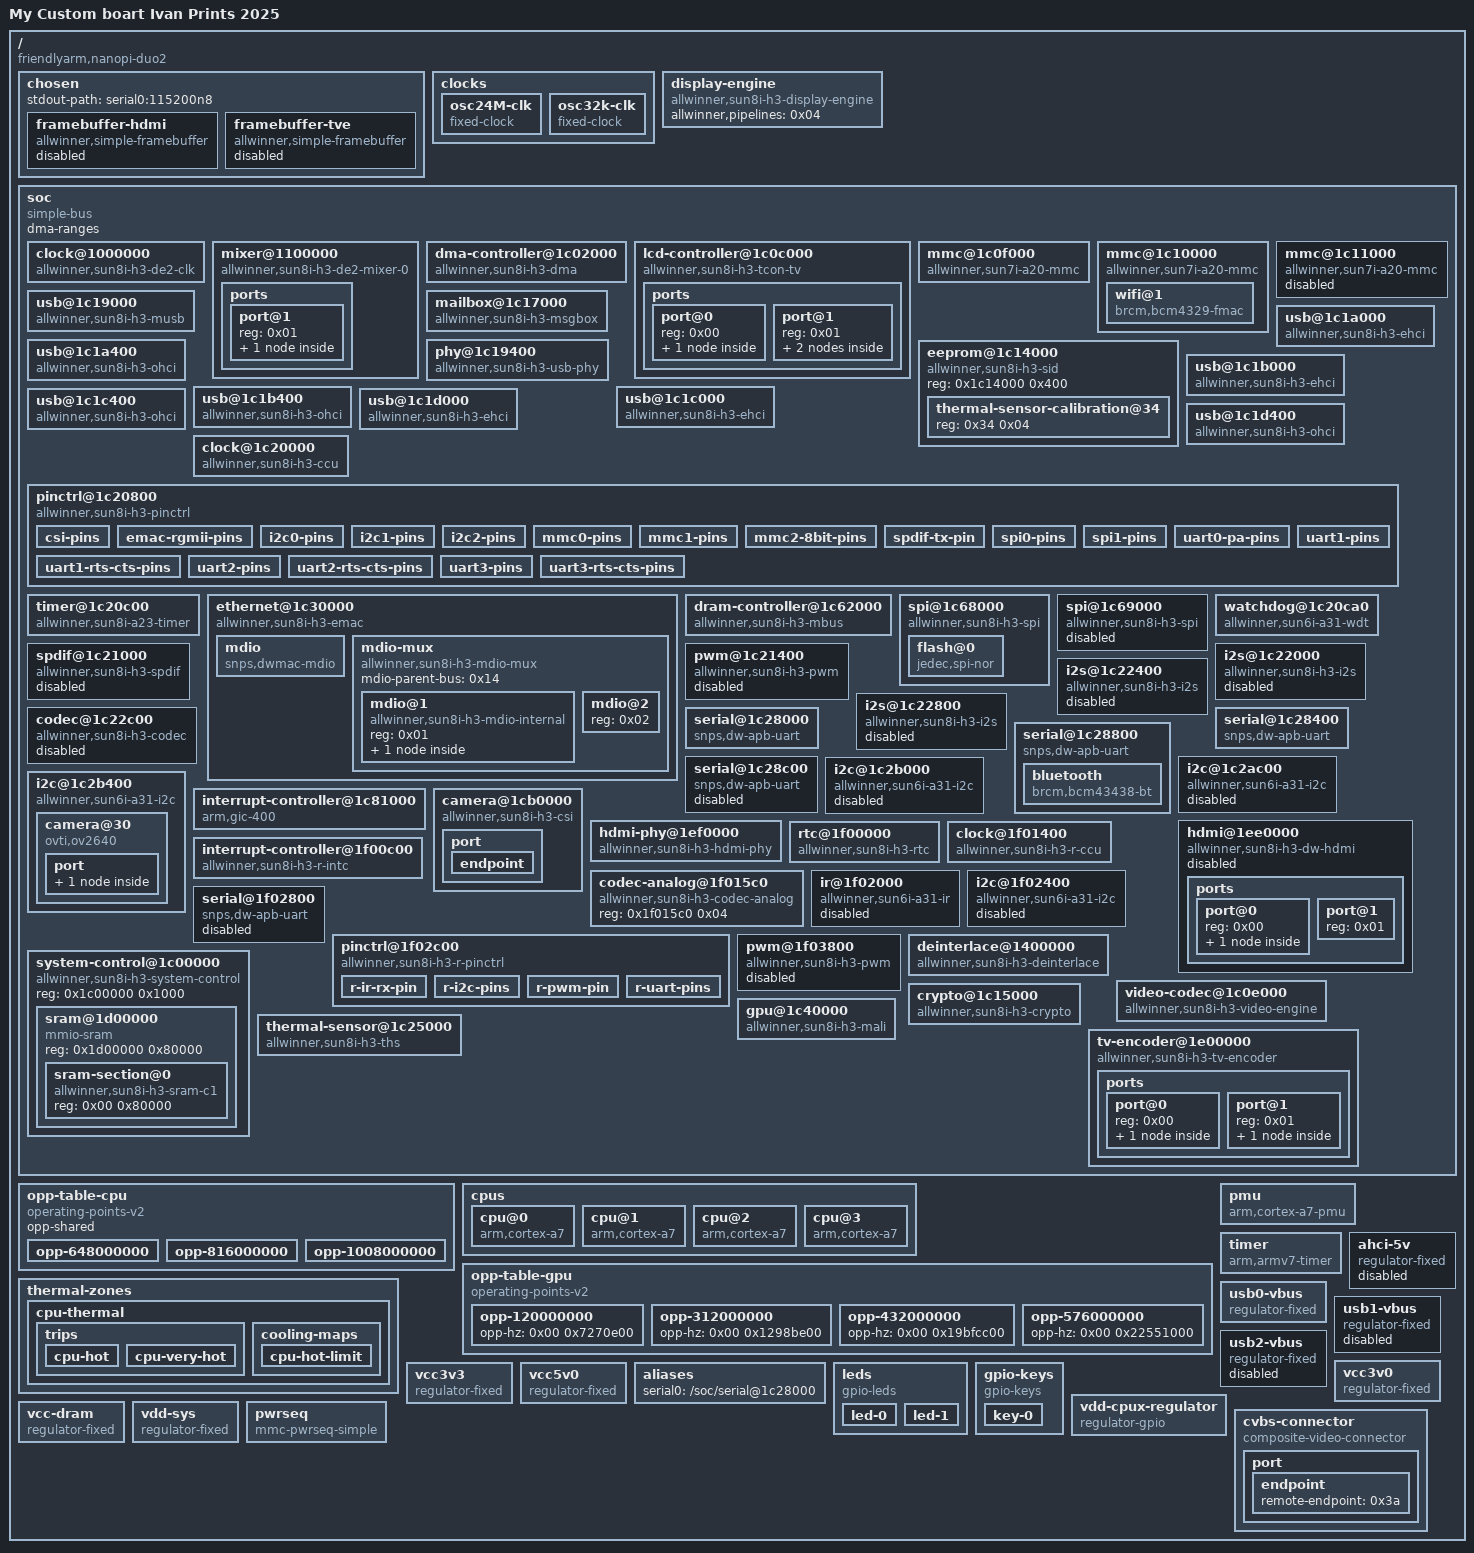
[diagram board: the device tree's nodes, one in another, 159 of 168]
/dts-v1/;

/ {
	interrupt-parent = <0x01>;
	#address-cells = <0x01>;
	#size-cells = <0x01>;
	model = "My Custom boart Ivan Prints 2025";
	compatible = "friendlyarm,nanopi-duo2\0allwinner,sun8i-h3";

	chosen {
		#address-cells = <0x01>;
		#size-cells = <0x01>;
		ranges;
		stdout-path = "serial0:115200n8";

		framebuffer-hdmi {
			compatible = "allwinner,simple-framebuffer\0simple-framebuffer";
			allwinner,pipeline = "mixer0-lcd0-hdmi";
			clocks = <0x02 0x06 0x03 0x66 0x03 0x6f>;
			status = "disabled";
		};

		framebuffer-tve {
			compatible = "allwinner,simple-framebuffer\0simple-framebuffer";
			allwinner,pipeline = "mixer1-lcd1-tve";
			clocks = <0x02 0x07 0x03 0x67>;
			status = "disabled";
		};
	};

	clocks {
		#address-cells = <0x01>;
		#size-cells = <0x01>;
		ranges;

		osc24M-clk {
			#clock-cells = <0x00>;
			compatible = "fixed-clock";
			clock-frequency = <0x16e3600>;
			clock-accuracy = <0xc350>;
			clock-output-names = "osc24M";
			phandle = <0x10>;
		};

		osc32k-clk {
			#clock-cells = <0x00>;
			compatible = "fixed-clock";
			clock-frequency = <0x8000>;
			clock-accuracy = <0xc350>;
			clock-output-names = "ext_osc32k";
			phandle = <0x25>;
		};
	};

	display-engine {
		compatible = "allwinner,sun8i-h3-display-engine";
		allwinner,pipelines = <0x04>;
		status = "okay";
	};

	soc {
		compatible = "simple-bus";
		#address-cells = <0x01>;
		#size-cells = <0x01>;
		dma-ranges;
		ranges;

		clock@1000000 {
			reg = <0x1000000 0x10000>;
			clocks = <0x03 0x30 0x03 0x65>;
			clock-names = "bus\0mod";
			resets = <0x03 0x22>;
			#clock-cells = <0x01>;
			#reset-cells = <0x01>;
			compatible = "allwinner,sun8i-h3-de2-clk";
			phandle = <0x02>;
		};

		mixer@1100000 {
			compatible = "allwinner,sun8i-h3-de2-mixer-0";
			reg = <0x1100000 0x100000>;
			clocks = <0x02 0x00 0x02 0x06>;
			clock-names = "bus\0mod";
			resets = <0x02 0x00>;
			status = "okay";
			phandle = <0x04>;

			ports {
				#address-cells = <0x01>;
				#size-cells = <0x00>;

				port@1 {
					reg = <0x01>;

					endpoint {
						remote-endpoint = <0x05>;
						phandle = <0x06>;
					};
				};
			};
		};

		dma-controller@1c02000 {
			compatible = "allwinner,sun8i-h3-dma";
			reg = <0x1c02000 0x1000>;
			interrupts = <0x00 0x32 0x04>;
			clocks = <0x03 0x15>;
			resets = <0x03 0x06>;
			#dma-cells = <0x01>;
			phandle = <0x15>;
		};

		lcd-controller@1c0c000 {
			compatible = "allwinner,sun8i-h3-tcon-tv\0allwinner,sun8i-a83t-tcon-tv";
			reg = <0x1c0c000 0x1000>;
			interrupts = <0x00 0x56 0x04>;
			clocks = <0x03 0x2a 0x03 0x66>;
			clock-names = "ahb\0tcon-ch1";
			resets = <0x03 0x1b>;
			reset-names = "lcd";
			status = "okay";

			ports {
				#address-cells = <0x01>;
				#size-cells = <0x00>;

				port@0 {
					reg = <0x00>;

					endpoint {
						remote-endpoint = <0x06>;
						phandle = <0x05>;
					};
				};

				port@1 {
					#address-cells = <0x01>;
					#size-cells = <0x00>;
					reg = <0x01>;

					endpoint@1 {
						reg = <0x01>;
						remote-endpoint = <0x07>;
						phandle = <0x24>;
					};

					endpoint@2 {
						reg = <0x02>;
						remote-endpoint = <0x08>;
						phandle = <0x2e>;
					};
				};
			};
		};

		mmc@1c0f000 {
			reg = <0x1c0f000 0x1000>;
			pinctrl-names = "default";
			pinctrl-0 = <0x09>;
			resets = <0x03 0x07>;
			reset-names = "ahb";
			interrupts = <0x00 0x3c 0x04>;
			status = "okay";
			#address-cells = <0x01>;
			#size-cells = <0x00>;
			compatible = "allwinner,sun7i-a20-mmc";
			clocks = <0x03 0x16 0x03 0x47 0x03 0x49 0x03 0x48>;
			clock-names = "ahb\0mmc\0output\0sample";
			bus-width = <0x04>;
			cd-gpios = <0x0a 0x05 0x06 0x01>;
			vmmc-supply = <0x0b>;
		};

		mmc@1c10000 {
			reg = <0x1c10000 0x1000>;
			pinctrl-names = "default";
			pinctrl-0 = <0x0c>;
			resets = <0x03 0x08>;
			reset-names = "ahb";
			interrupts = <0x00 0x3d 0x04>;
			status = "okay";
			#address-cells = <0x01>;
			#size-cells = <0x00>;
			compatible = "allwinner,sun7i-a20-mmc";
			clocks = <0x03 0x17 0x03 0x4a 0x03 0x4c 0x03 0x4b>;
			clock-names = "ahb\0mmc\0output\0sample";
			vmmc-supply = <0x0b>;
			vqmmc-supply = <0x0b>;
			mmc-pwrseq = <0x0d>;
			bus-width = <0x04>;
			non-removable;

			wifi@1 {
				reg = <0x01>;
				compatible = "brcm,bcm4329-fmac";
				interrupt-parent = <0x0a>;
				interrupts = <0x06 0x0a 0x08>;
				interrupt-names = "host-wake";
			};
		};

		mmc@1c11000 {
			reg = <0x1c11000 0x1000>;
			resets = <0x03 0x09>;
			reset-names = "ahb";
			interrupts = <0x00 0x3e 0x04>;
			status = "disabled";
			#address-cells = <0x01>;
			#size-cells = <0x00>;
			compatible = "allwinner,sun7i-a20-mmc";
			clocks = <0x03 0x18 0x03 0x4d 0x03 0x4f 0x03 0x4e>;
			clock-names = "ahb\0mmc\0output\0sample";
		};

		eeprom@1c14000 {
			reg = <0x1c14000 0x400>;
			#address-cells = <0x01>;
			#size-cells = <0x01>;
			compatible = "allwinner,sun8i-h3-sid";

			thermal-sensor-calibration@34 {
				reg = <0x34 0x04>;
				phandle = <0x2d>;
			};
		};

		mailbox@1c17000 {
			compatible = "allwinner,sun8i-h3-msgbox\0allwinner,sun6i-a31-msgbox";
			reg = <0x1c17000 0x1000>;
			clocks = <0x03 0x32>;
			resets = <0x03 0x24>;
			interrupts = <0x00 0x31 0x04>;
			#mbox-cells = <0x01>;
		};

		usb@1c19000 {
			compatible = "allwinner,sun8i-h3-musb";
			reg = <0x1c19000 0x400>;
			clocks = <0x03 0x20>;
			resets = <0x03 0x11>;
			interrupts = <0x00 0x47 0x04>;
			interrupt-names = "mc";
			phys = <0x0e 0x00>;
			phy-names = "usb";
			extcon = <0x0e 0x00>;
			dr_mode = "otg";
			status = "okay";
		};

		phy@1c19400 {
			compatible = "allwinner,sun8i-h3-usb-phy";
			reg = <0x1c19400 0x2c 0x1c1a800 0x04 0x1c1b800 0x04 0x1c1c800 0x04 0x1c1d800 0x04>;
			reg-names = "phy_ctrl\0pmu0\0pmu1\0pmu2\0pmu3";
			clocks = <0x03 0x58 0x03 0x59 0x03 0x5a 0x03 0x5b>;
			clock-names = "usb0_phy\0usb1_phy\0usb2_phy\0usb3_phy";
			resets = <0x03 0x00 0x03 0x01 0x03 0x02 0x03 0x03>;
			reset-names = "usb0_reset\0usb1_reset\0usb2_reset\0usb3_reset";
			status = "okay";
			#phy-cells = <0x01>;
			usb0_id_det-gpios = <0x0a 0x06 0x0c 0x00>;
			usb0_vbus-supply = <0x0f>;
			phandle = <0x0e>;
		};

		usb@1c1a000 {
			compatible = "allwinner,sun8i-h3-ehci\0generic-ehci";
			reg = <0x1c1a000 0x100>;
			interrupts = <0x00 0x48 0x04>;
			clocks = <0x03 0x21 0x03 0x25>;
			resets = <0x03 0x12 0x03 0x16>;
			phys = <0x0e 0x00>;
			phy-names = "usb";
			status = "okay";
		};

		usb@1c1a400 {
			compatible = "allwinner,sun8i-h3-ohci\0generic-ohci";
			reg = <0x1c1a400 0x100>;
			interrupts = <0x00 0x49 0x04>;
			clocks = <0x03 0x21 0x03 0x25 0x03 0x5c>;
			resets = <0x03 0x12 0x03 0x16>;
			phys = <0x0e 0x00>;
			phy-names = "usb";
			status = "okay";
		};

		usb@1c1b000 {
			compatible = "allwinner,sun8i-h3-ehci\0generic-ehci";
			reg = <0x1c1b000 0x100>;
			interrupts = <0x00 0x4a 0x04>;
			clocks = <0x03 0x22 0x03 0x26>;
			resets = <0x03 0x13 0x03 0x17>;
			phys = <0x0e 0x01>;
			phy-names = "usb";
			status = "okay";
		};

		usb@1c1b400 {
			compatible = "allwinner,sun8i-h3-ohci\0generic-ohci";
			reg = <0x1c1b400 0x100>;
			interrupts = <0x00 0x4b 0x04>;
			clocks = <0x03 0x22 0x03 0x26 0x03 0x5d>;
			resets = <0x03 0x13 0x03 0x17>;
			phys = <0x0e 0x01>;
			phy-names = "usb";
			status = "okay";
		};

		usb@1c1c000 {
			compatible = "allwinner,sun8i-h3-ehci\0generic-ehci";
			reg = <0x1c1c000 0x100>;
			interrupts = <0x00 0x4c 0x04>;
			clocks = <0x03 0x23 0x03 0x27>;
			resets = <0x03 0x14 0x03 0x18>;
			phys = <0x0e 0x02>;
			phy-names = "usb";
			status = "okay";
		};

		usb@1c1c400 {
			compatible = "allwinner,sun8i-h3-ohci\0generic-ohci";
			reg = <0x1c1c400 0x100>;
			interrupts = <0x00 0x4d 0x04>;
			clocks = <0x03 0x23 0x03 0x27 0x03 0x5e>;
			resets = <0x03 0x14 0x03 0x18>;
			phys = <0x0e 0x02>;
			phy-names = "usb";
			status = "okay";
		};

		usb@1c1d000 {
			compatible = "allwinner,sun8i-h3-ehci\0generic-ehci";
			reg = <0x1c1d000 0x100>;
			interrupts = <0x00 0x4e 0x04>;
			clocks = <0x03 0x24 0x03 0x28>;
			resets = <0x03 0x15 0x03 0x19>;
			phys = <0x0e 0x03>;
			phy-names = "usb";
			status = "okay";
		};

		usb@1c1d400 {
			compatible = "allwinner,sun8i-h3-ohci\0generic-ohci";
			reg = <0x1c1d400 0x100>;
			interrupts = <0x00 0x4f 0x04>;
			clocks = <0x03 0x24 0x03 0x28 0x03 0x5f>;
			resets = <0x03 0x15 0x03 0x19>;
			phys = <0x0e 0x03>;
			phy-names = "usb";
			status = "okay";
		};

		clock@1c20000 {
			reg = <0x1c20000 0x400>;
			clocks = <0x10 0x11 0x00>;
			clock-names = "hosc\0losc";
			#clock-cells = <0x01>;
			#reset-cells = <0x01>;
			compatible = "allwinner,sun8i-h3-ccu";
			phandle = <0x03>;
		};

		pinctrl@1c20800 {
			reg = <0x1c20800 0x400>;
			interrupts = <0x00 0x0b 0x04 0x00 0x11 0x04>;
			clocks = <0x03 0x36 0x10 0x11 0x00>;
			clock-names = "apb\0hosc\0losc";
			gpio-controller;
			#gpio-cells = <0x03>;
			interrupt-controller;
			#interrupt-cells = <0x03>;
			compatible = "allwinner,sun8i-h3-pinctrl";
			phandle = <0x0a>;

			csi-pins {
				pins = "PE0\0PE2\0PE3\0PE4\0PE5\0PE6\0PE7\0PE8\0PE9\0PE10\0PE11";
				function = "csi";
				phandle = <0x21>;
			};

			emac-rgmii-pins {
				pins = "PD0\0PD1\0PD2\0PD3\0PD4\0PD5\0PD7\0PD8\0PD9\0PD10\0PD12\0PD13\0PD15\0PD16\0PD17";
				function = "emac";
				drive-strength = <0x28>;
			};

			i2c0-pins {
				pins = "PA11\0PA12";
				function = "i2c0";
				phandle = <0x1d>;
			};

			i2c1-pins {
				pins = "PA18\0PA19";
				function = "i2c1";
				phandle = <0x1e>;
			};

			i2c2-pins {
				pins = "PE12\0PE13";
				function = "i2c2";
				phandle = <0x1f>;
			};

			mmc0-pins {
				pins = "PF0\0PF1\0PF2\0PF3\0PF4\0PF5";
				function = "mmc0";
				drive-strength = <0x1e>;
				bias-pull-up;
				phandle = <0x09>;
			};

			mmc1-pins {
				pins = "PG0\0PG1\0PG2\0PG3\0PG4\0PG5";
				function = "mmc1";
				drive-strength = <0x1e>;
				bias-pull-up;
				phandle = <0x0c>;
			};

			mmc2-8bit-pins {
				pins = "PC5\0PC6\0PC8\0PC9\0PC10\0PC11\0PC12\0PC13\0PC14\0PC15\0PC16";
				function = "mmc2";
				drive-strength = <0x1e>;
				bias-pull-up;
			};

			spdif-tx-pin {
				pins = "PA17";
				function = "spdif";
			};

			spi0-pins {
				pins = "PC0\0PC1\0PC2\0PC3";
				function = "spi0";
				phandle = <0x16>;
			};

			spi1-pins {
				pins = "PA15\0PA16\0PA14\0PA13";
				function = "spi1";
				phandle = <0x17>;
			};

			uart0-pa-pins {
				pins = "PA4\0PA5";
				function = "uart0";
				phandle = <0x19>;
			};

			uart1-pins {
				pins = "PG6\0PG7";
				function = "uart1";
				phandle = <0x1a>;
			};

			uart1-rts-cts-pins {
				pins = "PG8\0PG9";
				function = "uart1";
			};

			uart2-pins {
				pins = "PA0\0PA1";
				function = "uart2";
				phandle = <0x1b>;
			};

			uart2-rts-cts-pins {
				pins = "PA2\0PA3";
				function = "uart2";
				phandle = <0x1c>;
			};

			uart3-pins {
				pins = "PA13\0PA14";
				function = "uart3";
			};

			uart3-rts-cts-pins {
				pins = "PA15\0PA16";
				function = "uart3";
			};
		};

		timer@1c20c00 {
			compatible = "allwinner,sun8i-a23-timer";
			reg = <0x1c20c00 0xa0>;
			interrupts = <0x00 0x12 0x04 0x00 0x13 0x04>;
			clocks = <0x10>;
		};

		ethernet@1c30000 {
			compatible = "allwinner,sun8i-h3-emac";
			syscon = <0x12>;
			reg = <0x1c30000 0x10000>;
			interrupts = <0x00 0x52 0x04>;
			interrupt-names = "macirq";
			resets = <0x03 0x0c>;
			reset-names = "stmmaceth";
			clocks = <0x03 0x1b>;
			clock-names = "stmmaceth";
			status = "okay";
			phy-handle = <0x13>;
			phy-mode = "mii";
			allwinner,leds-active-low;

			mdio {
				#address-cells = <0x01>;
				#size-cells = <0x00>;
				compatible = "snps,dwmac-mdio";
				phandle = <0x14>;
			};

			mdio-mux {
				compatible = "allwinner,sun8i-h3-mdio-mux";
				#address-cells = <0x01>;
				#size-cells = <0x00>;
				mdio-parent-bus = <0x14>;

				mdio@1 {
					compatible = "allwinner,sun8i-h3-mdio-internal";
					reg = <0x01>;
					#address-cells = <0x01>;
					#size-cells = <0x00>;

					ethernet-phy@1 {
						compatible = "ethernet-phy-ieee802.3-c22";
						reg = <0x01>;
						clocks = <0x03 0x43>;
						resets = <0x03 0x27>;
						phandle = <0x13>;
					};
				};

				mdio@2 {
					reg = <0x02>;
					#address-cells = <0x01>;
					#size-cells = <0x00>;
				};
			};
		};

		dram-controller@1c62000 {
			reg = <0x1c62000 0x1000 0x1c63000 0x1000>;
			reg-names = "mbus\0dram";
			clocks = <0x03 0x71 0x03 0x60 0x03 0x1a>;
			clock-names = "mbus\0dram\0bus";
			#address-cells = <0x01>;
			#size-cells = <0x01>;
			dma-ranges = <0x00 0x40000000 0xc0000000>;
			#interconnect-cells = <0x01>;
			compatible = "allwinner,sun8i-h3-mbus";
			phandle = <0x2a>;
		};

		spi@1c68000 {
			compatible = "allwinner,sun8i-h3-spi";
			reg = <0x1c68000 0x1000>;
			interrupts = <0x00 0x41 0x04>;
			clocks = <0x03 0x1e 0x03 0x52>;
			clock-names = "ahb\0mod";
			dmas = <0x15 0x17 0x15 0x17>;
			dma-names = "rx\0tx";
			pinctrl-names = "default";
			pinctrl-0 = <0x16>;
			resets = <0x03 0x0f>;
			status = "okay";
			#address-cells = <0x01>;
			#size-cells = <0x00>;

			flash@0 {
				compatible = "jedec,spi-nor";
				reg = <0x00>;
				spi-max-frequency = <0x2faf080>;
			};
		};

		spi@1c69000 {
			compatible = "allwinner,sun8i-h3-spi";
			reg = <0x1c69000 0x1000>;
			interrupts = <0x00 0x42 0x04>;
			clocks = <0x03 0x1f 0x03 0x53>;
			clock-names = "ahb\0mod";
			dmas = <0x15 0x18 0x15 0x18>;
			dma-names = "rx\0tx";
			pinctrl-names = "default";
			pinctrl-0 = <0x17>;
			resets = <0x03 0x10>;
			status = "disabled";
			#address-cells = <0x01>;
			#size-cells = <0x00>;
		};

		watchdog@1c20ca0 {
			compatible = "allwinner,sun6i-a31-wdt";
			reg = <0x1c20ca0 0x20>;
			interrupts = <0x00 0x19 0x04>;
			clocks = <0x10>;
		};

		spdif@1c21000 {
			#sound-dai-cells = <0x00>;
			compatible = "allwinner,sun8i-h3-spdif";
			reg = <0x1c21000 0x400>;
			interrupts = <0x00 0x0c 0x04>;
			clocks = <0x03 0x35 0x03 0x57>;
			resets = <0x03 0x29>;
			clock-names = "apb\0spdif";
			dmas = <0x15 0x02>;
			dma-names = "tx";
			status = "disabled";
		};

		pwm@1c21400 {
			compatible = "allwinner,sun8i-h3-pwm";
			reg = <0x1c21400 0x08>;
			clocks = <0x10>;
			#pwm-cells = <0x03>;
			status = "disabled";
		};

		i2s@1c22000 {
			#sound-dai-cells = <0x00>;
			compatible = "allwinner,sun8i-h3-i2s";
			reg = <0x1c22000 0x400>;
			interrupts = <0x00 0x0d 0x04>;
			clocks = <0x03 0x38 0x03 0x54>;
			clock-names = "apb\0mod";
			dmas = <0x15 0x03 0x15 0x03>;
			resets = <0x03 0x2b>;
			dma-names = "rx\0tx";
			status = "disabled";
		};

		i2s@1c22400 {
			#sound-dai-cells = <0x00>;
			compatible = "allwinner,sun8i-h3-i2s";
			reg = <0x1c22400 0x400>;
			interrupts = <0x00 0x0e 0x04>;
			clocks = <0x03 0x39 0x03 0x55>;
			clock-names = "apb\0mod";
			dmas = <0x15 0x04 0x15 0x04>;
			resets = <0x03 0x2c>;
			dma-names = "rx\0tx";
			status = "disabled";
		};

		i2s@1c22800 {
			#sound-dai-cells = <0x00>;
			compatible = "allwinner,sun8i-h3-i2s";
			reg = <0x1c22800 0x400>;
			interrupts = <0x00 0x0f 0x04>;
			clocks = <0x03 0x3a 0x03 0x56>;
			clock-names = "apb\0mod";
			dmas = <0x15 0x1b>;
			resets = <0x03 0x2d>;
			dma-names = "tx";
			status = "disabled";
		};

		codec@1c22c00 {
			#sound-dai-cells = <0x00>;
			compatible = "allwinner,sun8i-h3-codec";
			reg = <0x1c22c00 0x400>;
			interrupts = <0x00 0x1d 0x04>;
			clocks = <0x03 0x34 0x03 0x6d>;
			clock-names = "apb\0codec";
			resets = <0x03 0x28>;
			dmas = <0x15 0x0f 0x15 0x0f>;
			dma-names = "rx\0tx";
			allwinner,codec-analog-controls = <0x18>;
			status = "disabled";
		};

		serial@1c28000 {
			compatible = "snps,dw-apb-uart";
			reg = <0x1c28000 0x400>;
			interrupts = <0x00 0x00 0x04>;
			reg-shift = <0x02>;
			reg-io-width = <0x04>;
			clocks = <0x03 0x3e>;
			resets = <0x03 0x31>;
			dmas = <0x15 0x06 0x15 0x06>;
			dma-names = "tx\0rx";
			status = "okay";
			pinctrl-names = "default";
			pinctrl-0 = <0x19>;
		};

		serial@1c28400 {
			compatible = "snps,dw-apb-uart";
			reg = <0x1c28400 0x400>;
			interrupts = <0x00 0x01 0x04>;
			reg-shift = <0x02>;
			reg-io-width = <0x04>;
			clocks = <0x03 0x3f>;
			resets = <0x03 0x32>;
			dmas = <0x15 0x07 0x15 0x07>;
			dma-names = "tx\0rx";
			status = "okay";
			pinctrl-names = "default";
			pinctrl-0 = <0x1a>;
		};

		serial@1c28800 {
			compatible = "snps,dw-apb-uart";
			reg = <0x1c28800 0x400>;
			interrupts = <0x00 0x02 0x04>;
			reg-shift = <0x02>;
			reg-io-width = <0x04>;
			clocks = <0x03 0x40>;
			resets = <0x03 0x33>;
			dmas = <0x15 0x08 0x15 0x08>;
			dma-names = "tx\0rx";
			status = "okay";
			pinctrl-names = "default";
			pinctrl-0 = <0x1b 0x1c>;
			uart-has-rtscts;

			bluetooth {
				compatible = "brcm,bcm43438-bt";
				clocks = <0x11 0x01>;
				clock-names = "lpo";
				vbat-supply = <0x0b>;
				vddio-supply = <0x0b>;
				device-wakeup-gpios = <0x0a 0x00 0x08 0x00>;
				host-wakeup-gpios = <0x0a 0x00 0x07 0x00>;
				shutdown-gpios = <0x0a 0x06 0x0d 0x00>;
			};
		};

		serial@1c28c00 {
			compatible = "snps,dw-apb-uart";
			reg = <0x1c28c00 0x400>;
			interrupts = <0x00 0x03 0x04>;
			reg-shift = <0x02>;
			reg-io-width = <0x04>;
			clocks = <0x03 0x41>;
			resets = <0x03 0x34>;
			dmas = <0x15 0x09 0x15 0x09>;
			dma-names = "tx\0rx";
			status = "disabled";
		};

		i2c@1c2ac00 {
			compatible = "allwinner,sun6i-a31-i2c";
			reg = <0x1c2ac00 0x400>;
			interrupts = <0x00 0x06 0x04>;
			clocks = <0x03 0x3b>;
			resets = <0x03 0x2e>;
			pinctrl-names = "default";
			pinctrl-0 = <0x1d>;
			status = "disabled";
			#address-cells = <0x01>;
			#size-cells = <0x00>;
		};

		i2c@1c2b000 {
			compatible = "allwinner,sun6i-a31-i2c";
			reg = <0x1c2b000 0x400>;
			interrupts = <0x00 0x07 0x04>;
			clocks = <0x03 0x3c>;
			resets = <0x03 0x2f>;
			pinctrl-names = "default";
			pinctrl-0 = <0x1e>;
			status = "disabled";
			#address-cells = <0x01>;
			#size-cells = <0x00>;
		};

		i2c@1c2b400 {
			compatible = "allwinner,sun6i-a31-i2c";
			reg = <0x1c2b400 0x400>;
			interrupts = <0x00 0x08 0x04>;
			clocks = <0x03 0x3d>;
			resets = <0x03 0x30>;
			pinctrl-names = "default";
			pinctrl-0 = <0x1f>;
			status = "okay";
			#address-cells = <0x01>;
			#size-cells = <0x00>;

			camera@30 {
				compatible = "ovti,ov2640";
				reg = <0x30>;
				clocks = <0x03 0x6b>;
				clock-names = "xclk";
				reset-gpios = <0x0a 0x04 0x0e 0x01>;
				powerdown-gpios = <0x0a 0x04 0x0f 0x00>;
				AVDD-supply = <0x0b>;
				DOVDD-supply = <0x0b>;
				DVDD-supply = <0x0b>;

				port {

					endpoint {
						remote-endpoint = <0x20>;
						bus-width = <0x08>;
						hsync-active = <0x01>;
						vsync-active = <0x00>;
						data-active = <0x01>;
						pclk-sample = <0x01>;
						phandle = <0x22>;
					};
				};
			};
		};

		interrupt-controller@1c81000 {
			compatible = "arm,gic-400";
			reg = <0x1c81000 0x1000 0x1c82000 0x2000 0x1c84000 0x2000 0x1c86000 0x2000>;
			interrupt-controller;
			#interrupt-cells = <0x03>;
			interrupts = <0x01 0x09 0xf04>;
			phandle = <0x01>;
		};

		camera@1cb0000 {
			compatible = "allwinner,sun8i-h3-csi";
			reg = <0x1cb0000 0x1000>;
			interrupts = <0x00 0x54 0x04>;
			clocks = <0x03 0x2d 0x03 0x6a 0x03 0x62>;
			clock-names = "bus\0mod\0ram";
			resets = <0x03 0x1e>;
			pinctrl-names = "default";
			pinctrl-0 = <0x21>;
			status = "okay";

			port {

				endpoint {
					remote-endpoint = <0x22>;
					bus-width = <0x08>;
					hsync-active = <0x01>;
					vsync-active = <0x00>;
					data-active = <0x01>;
					pclk-sample = <0x01>;
					phandle = <0x20>;
				};
			};
		};

		hdmi@1ee0000 {
			compatible = "allwinner,sun8i-h3-dw-hdmi\0allwinner,sun8i-a83t-dw-hdmi";
			reg = <0x1ee0000 0x10000>;
			reg-io-width = <0x01>;
			interrupts = <0x00 0x58 0x04>;
			clocks = <0x03 0x2f 0x03 0x70 0x03 0x6f 0x11 0x00>;
			clock-names = "iahb\0isfr\0tmds\0cec";
			resets = <0x03 0x21>;
			reset-names = "ctrl";
			phys = <0x23>;
			phy-names = "phy";
			status = "disabled";

			ports {
				#address-cells = <0x01>;
				#size-cells = <0x00>;

				port@0 {
					reg = <0x00>;

					endpoint {
						remote-endpoint = <0x24>;
						phandle = <0x07>;
					};
				};

				port@1 {
					reg = <0x01>;
				};
			};
		};

		hdmi-phy@1ef0000 {
			compatible = "allwinner,sun8i-h3-hdmi-phy";
			reg = <0x1ef0000 0x10000>;
			clocks = <0x03 0x2f 0x03 0x70 0x03 0x06>;
			clock-names = "bus\0mod\0pll-0";
			resets = <0x03 0x20>;
			reset-names = "phy";
			#phy-cells = <0x00>;
			phandle = <0x23>;
		};

		rtc@1f00000 {
			reg = <0x1f00000 0x400>;
			interrupts = <0x00 0x28 0x04 0x00 0x29 0x04>;
			clock-output-names = "osc32k\0osc32k-out\0iosc";
			clocks = <0x25>;
			#clock-cells = <0x01>;
			compatible = "allwinner,sun8i-h3-rtc";
			phandle = <0x11>;
		};

		interrupt-controller@1f00c00 {
			compatible = "allwinner,sun8i-h3-r-intc\0allwinner,sun6i-a31-r-intc";
			interrupt-controller;
			#interrupt-cells = <0x03>;
			reg = <0x1f00c00 0x400>;
			interrupts = <0x00 0x20 0x04>;
		};

		clock@1f01400 {
			compatible = "allwinner,sun8i-h3-r-ccu";
			reg = <0x1f01400 0x100>;
			clocks = <0x10 0x11 0x00 0x11 0x02 0x03 0x09>;
			clock-names = "hosc\0losc\0iosc\0pll-periph";
			#clock-cells = <0x01>;
			#reset-cells = <0x01>;
			phandle = <0x26>;
		};

		codec-analog@1f015c0 {
			compatible = "allwinner,sun8i-h3-codec-analog";
			reg = <0x1f015c0 0x04>;
			phandle = <0x18>;
		};

		ir@1f02000 {
			compatible = "allwinner,sun6i-a31-ir";
			clocks = <0x26 0x04 0x26 0x0b>;
			clock-names = "apb\0ir";
			resets = <0x26 0x00>;
			interrupts = <0x00 0x25 0x04>;
			reg = <0x1f02000 0x400>;
			status = "disabled";
		};

		i2c@1f02400 {
			compatible = "allwinner,sun6i-a31-i2c";
			reg = <0x1f02400 0x400>;
			interrupts = <0x00 0x2c 0x04>;
			pinctrl-names = "default";
			pinctrl-0 = <0x27>;
			clocks = <0x26 0x09>;
			resets = <0x26 0x05>;
			status = "disabled";
			#address-cells = <0x01>;
			#size-cells = <0x00>;
		};

		serial@1f02800 {
			compatible = "snps,dw-apb-uart";
			reg = <0x1f02800 0x400>;
			interrupts = <0x00 0x26 0x04>;
			reg-shift = <0x02>;
			reg-io-width = <0x04>;
			clocks = <0x26 0x07>;
			resets = <0x26 0x03>;
			pinctrl-names = "default";
			pinctrl-0 = <0x28>;
			status = "disabled";
		};

		pinctrl@1f02c00 {
			compatible = "allwinner,sun8i-h3-r-pinctrl";
			reg = <0x1f02c00 0x400>;
			interrupts = <0x00 0x2d 0x04>;
			clocks = <0x26 0x03 0x10 0x11 0x00>;
			clock-names = "apb\0hosc\0losc";
			gpio-controller;
			#gpio-cells = <0x03>;
			interrupt-controller;
			#interrupt-cells = <0x03>;
			phandle = <0x38>;

			r-ir-rx-pin {
				pins = "PL11";
				function = "s_cir_rx";
			};

			r-i2c-pins {
				pins = "PL0\0PL1";
				function = "s_i2c";
				phandle = <0x27>;
			};

			r-pwm-pin {
				pins = "PL10";
				function = "s_pwm";
				phandle = <0x29>;
			};

			r-uart-pins {
				pins = "PL2\0PL3";
				function = "s_uart";
				phandle = <0x28>;
			};
		};

		pwm@1f03800 {
			compatible = "allwinner,sun8i-h3-pwm";
			reg = <0x1f03800 0x08>;
			pinctrl-names = "default";
			pinctrl-0 = <0x29>;
			clocks = <0x10>;
			#pwm-cells = <0x03>;
			status = "disabled";
		};

		deinterlace@1400000 {
			compatible = "allwinner,sun8i-h3-deinterlace";
			reg = <0x1400000 0x20000>;
			clocks = <0x03 0x2c 0x03 0x68 0x03 0x63>;
			clock-names = "bus\0mod\0ram";
			resets = <0x03 0x1d>;
			interrupts = <0x00 0x5d 0x04>;
			interconnects = <0x2a 0x09>;
			interconnect-names = "dma-mem";
		};

		system-control@1c00000 {
			compatible = "allwinner,sun8i-h3-system-control";
			reg = <0x1c00000 0x1000>;
			#address-cells = <0x01>;
			#size-cells = <0x01>;
			ranges;
			phandle = <0x12>;

			sram@1d00000 {
				compatible = "mmio-sram";
				reg = <0x1d00000 0x80000>;
				#address-cells = <0x01>;
				#size-cells = <0x01>;
				ranges = <0x00 0x1d00000 0x80000>;

				sram-section@0 {
					compatible = "allwinner,sun8i-h3-sram-c1\0allwinner,sun4i-a10-sram-c1";
					reg = <0x00 0x80000>;
					phandle = <0x2b>;
				};
			};
		};

		video-codec@1c0e000 {
			compatible = "allwinner,sun8i-h3-video-engine";
			reg = <0x1c0e000 0x1000>;
			clocks = <0x03 0x29 0x03 0x6c 0x03 0x61>;
			clock-names = "ahb\0mod\0ram";
			resets = <0x03 0x1a>;
			interrupts = <0x00 0x3a 0x04>;
			allwinner,sram = <0x2b 0x01>;
		};

		crypto@1c15000 {
			compatible = "allwinner,sun8i-h3-crypto";
			reg = <0x1c15000 0x1000>;
			interrupts = <0x00 0x5e 0x04>;
			clocks = <0x03 0x14 0x03 0x51>;
			clock-names = "bus\0mod";
			resets = <0x03 0x05>;
		};

		gpu@1c40000 {
			compatible = "allwinner,sun8i-h3-mali\0arm,mali-400";
			reg = <0x1c40000 0x10000>;
			interrupts = <0x00 0x61 0x04 0x00 0x62 0x04 0x00 0x63 0x04 0x00 0x64 0x04 0x00 0x66 0x04 0x00 0x67 0x04 0x00 0x65 0x04>;
			interrupt-names = "gp\0gpmmu\0pp0\0ppmmu0\0pp1\0ppmmu1\0pmu";
			clocks = <0x03 0x31 0x03 0x72>;
			clock-names = "bus\0core";
			resets = <0x03 0x23>;
			operating-points-v2 = <0x2c>;
		};

		thermal-sensor@1c25000 {
			compatible = "allwinner,sun8i-h3-ths";
			reg = <0x1c25000 0x400>;
			interrupts = <0x00 0x1f 0x04>;
			resets = <0x03 0x2a>;
			clocks = <0x03 0x37 0x03 0x45>;
			clock-names = "bus\0mod";
			nvmem-cells = <0x2d>;
			nvmem-cell-names = "calibration";
			#thermal-sensor-cells = <0x00>;
			phandle = <0x36>;
		};

		tv-encoder@1e00000 {
			compatible = "allwinner,sun8i-h3-tv-encoder";
			reg = <0x1e00000 0x1000>;
			clocks = <0x03 0x2e>;
			resets = <0x03 0x1f>;
			status = "okay";

			ports {
				#address-cells = <0x01>;
				#size-cells = <0x00>;

				port@0 {
					reg = <0x00>;

					endpoint {
						remote-endpoint = <0x2e>;
						phandle = <0x08>;
					};
				};

				port@1 {
					reg = <0x01>;

					endpoint {
						remote-endpoint = <0x2f>;
						phandle = <0x3a>;
					};
				};
			};
		};
	};

	opp-table-cpu {
		compatible = "operating-points-v2";
		opp-shared;
		phandle = <0x30>;

		opp-648000000 {
			opp-hz = <0x00 0x269fb200>;
			opp-microvolt = <0xfde80 0xfde80 0x13d620>;
			clock-latency-ns = <0x3b9b0>;
		};

		opp-816000000 {
			opp-hz = <0x00 0x30a32c00>;
			opp-microvolt = <0x10c8e0 0x10c8e0 0x13d620>;
			clock-latency-ns = <0x3b9b0>;
		};

		opp-1008000000 {
			opp-hz = <0x00 0x3c14dc00>;
			opp-microvolt = <0x124f80 0x124f80 0x13d620>;
			clock-latency-ns = <0x3b9b0>;
		};
	};

	cpus {
		#address-cells = <0x01>;
		#size-cells = <0x00>;

		cpu@0 {
			compatible = "arm,cortex-a7";
			device_type = "cpu";
			reg = <0x00>;
			clocks = <0x03 0x0e>;
			clock-names = "cpu";
			operating-points-v2 = <0x30>;
			#cooling-cells = <0x02>;
			cpu-supply = <0x31>;
			phandle = <0x32>;
		};

		cpu@1 {
			compatible = "arm,cortex-a7";
			device_type = "cpu";
			reg = <0x01>;
			clocks = <0x03 0x0e>;
			clock-names = "cpu";
			operating-points-v2 = <0x30>;
			#cooling-cells = <0x02>;
			phandle = <0x33>;
		};

		cpu@2 {
			compatible = "arm,cortex-a7";
			device_type = "cpu";
			reg = <0x02>;
			clocks = <0x03 0x0e>;
			clock-names = "cpu";
			operating-points-v2 = <0x30>;
			#cooling-cells = <0x02>;
			phandle = <0x34>;
		};

		cpu@3 {
			compatible = "arm,cortex-a7";
			device_type = "cpu";
			reg = <0x03>;
			clocks = <0x03 0x0e>;
			clock-names = "cpu";
			operating-points-v2 = <0x30>;
			#cooling-cells = <0x02>;
			phandle = <0x35>;
		};
	};

	opp-table-gpu {
		compatible = "operating-points-v2";
		phandle = <0x2c>;

		opp-120000000 {
			opp-hz = <0x00 0x7270e00>;
		};

		opp-312000000 {
			opp-hz = <0x00 0x1298be00>;
		};

		opp-432000000 {
			opp-hz = <0x00 0x19bfcc00>;
		};

		opp-576000000 {
			opp-hz = <0x00 0x22551000>;
		};
	};

	pmu {
		compatible = "arm,cortex-a7-pmu";
		interrupts = <0x00 0x78 0x04 0x00 0x79 0x04 0x00 0x7a 0x04 0x00 0x7b 0x04>;
		interrupt-affinity = <0x32 0x33 0x34 0x35>;
	};

	timer {
		compatible = "arm,armv7-timer";
		interrupts = <0x01 0x0d 0xf08 0x01 0x0e 0xf08 0x01 0x0b 0xf08 0x01 0x0a 0xf08>;
	};

	thermal-zones {

		cpu-thermal {
			polling-delay-passive = <0x00>;
			polling-delay = <0x00>;
			thermal-sensors = <0x36>;

			trips {

				cpu-hot {
					temperature = <0x13880>;
					hysteresis = <0x7d0>;
					type = "passive";
					phandle = <0x37>;
				};

				cpu-very-hot {
					temperature = <0x186a0>;
					hysteresis = <0x00>;
					type = "critical";
				};
			};

			cooling-maps {

				cpu-hot-limit {
					trip = <0x37>;
					cooling-device = <0x32 0xffffffff 0xffffffff 0x33 0xffffffff 0xffffffff 0x34 0xffffffff 0xffffffff 0x35 0xffffffff 0xffffffff>;
				};
			};
		};
	};

	ahci-5v {
		compatible = "regulator-fixed";
		regulator-name = "ahci-5v";
		regulator-min-microvolt = <0x4c4b40>;
		regulator-max-microvolt = <0x4c4b40>;
		regulator-boot-on;
		enable-active-high;
		gpio = <0x0a 0x01 0x08 0x00>;
		status = "disabled";
	};

	usb0-vbus {
		compatible = "regulator-fixed";
		regulator-name = "usb0-vbus";
		regulator-min-microvolt = <0x4c4b40>;
		regulator-max-microvolt = <0x4c4b40>;
		enable-active-high;
		gpio = <0x38 0x00 0x02 0x00>;
		status = "okay";
		phandle = <0x0f>;
	};

	usb1-vbus {
		compatible = "regulator-fixed";
		regulator-name = "usb1-vbus";
		regulator-min-microvolt = <0x4c4b40>;
		regulator-max-microvolt = <0x4c4b40>;
		regulator-boot-on;
		enable-active-high;
		gpio = <0x0a 0x07 0x06 0x00>;
		status = "disabled";
	};

	usb2-vbus {
		compatible = "regulator-fixed";
		regulator-name = "usb2-vbus";
		regulator-min-microvolt = <0x4c4b40>;
		regulator-max-microvolt = <0x4c4b40>;
		regulator-boot-on;
		enable-active-high;
		gpio = <0x0a 0x07 0x03 0x00>;
		status = "disabled";
	};

	vcc3v0 {
		compatible = "regulator-fixed";
		regulator-name = "vcc3v0";
		regulator-min-microvolt = <0x2dc6c0>;
		regulator-max-microvolt = <0x2dc6c0>;
	};

	vcc3v3 {
		compatible = "regulator-fixed";
		regulator-name = "vcc3v3";
		regulator-min-microvolt = <0x325aa0>;
		regulator-max-microvolt = <0x325aa0>;
		phandle = <0x0b>;
	};

	vcc5v0 {
		compatible = "regulator-fixed";
		regulator-name = "vcc5v0";
		regulator-min-microvolt = <0x4c4b40>;
		regulator-max-microvolt = <0x4c4b40>;
		phandle = <0x39>;
	};

	aliases {
		serial0 = "/soc/serial@1c28000";
	};

	leds {
		compatible = "gpio-leds";

		led-0 {
			label = "red_pwr";
			gpios = <0x38 0x00 0x0a 0x00>;
			#default-state = "on";
			linux,default-trigger = "heartbeat";
		};

		led-1 {
			label = "green_status";
			gpios = <0x0a 0x00 0x0a 0x00>;
			#default-state = "on";
			linux,default-trigger = "cpu";
		};
	};

	gpio-keys {
		compatible = "gpio-keys";

		key-0 {
			label = "k1";
			linux,code = <0x100>;
			gpios = <0x38 0x00 0x03 0x01>;
		};
	};

	vdd-cpux-regulator {
		compatible = "regulator-gpio";
		regulator-name = "vdd-cpux";
		regulator-min-microvolt = <0x10c8e0>;
		regulator-max-microvolt = <0x13d620>;
		regulator-always-on;
		regulator-boot-on;
		regulator-ramp-delay = <0x32>;
		enable-active-high;
		enable-gpios = <0x38 0x00 0x08 0x00>;
		gpios = <0x38 0x00 0x06 0x00>;
		gpios-states = <0x01>;
		states = <0x10c8e0 0x00 0x13d620 0x01>;
		phandle = <0x31>;
	};

	vcc-dram {
		compatible = "regulator-fixed";
		regulator-name = "vcc-dram";
		regulator-min-microvolt = <0x16e360>;
		regulator-max-microvolt = <0x16e360>;
		regulator-always-on;
		regulator-boot-on;
		enable-active-high;
		gpio = <0x38 0x00 0x09 0x00>;
		vin-supply = <0x39>;
	};

	vdd-sys {
		compatible = "regulator-fixed";
		regulator-name = "vdd-sys";
		regulator-min-microvolt = <0x124f80>;
		regulator-max-microvolt = <0x124f80>;
		regulator-always-on;
		regulator-boot-on;
		enable-active-high;
		gpio = <0x38 0x00 0x08 0x00>;
		vin-supply = <0x39>;
	};

	pwrseq {
		compatible = "mmc-pwrseq-simple";
		reset-gpios = <0x38 0x00 0x07 0x01>;
		clocks = <0x11 0x01>;
		clock-names = "ext_clock";
		phandle = <0x0d>;
	};

	cvbs-connector {
		compatible = "composite-video-connector";

		port {

			endpoint {
				remote-endpoint = <0x3a>;
				phandle = <0x2f>;
			};
		};
	};
};
